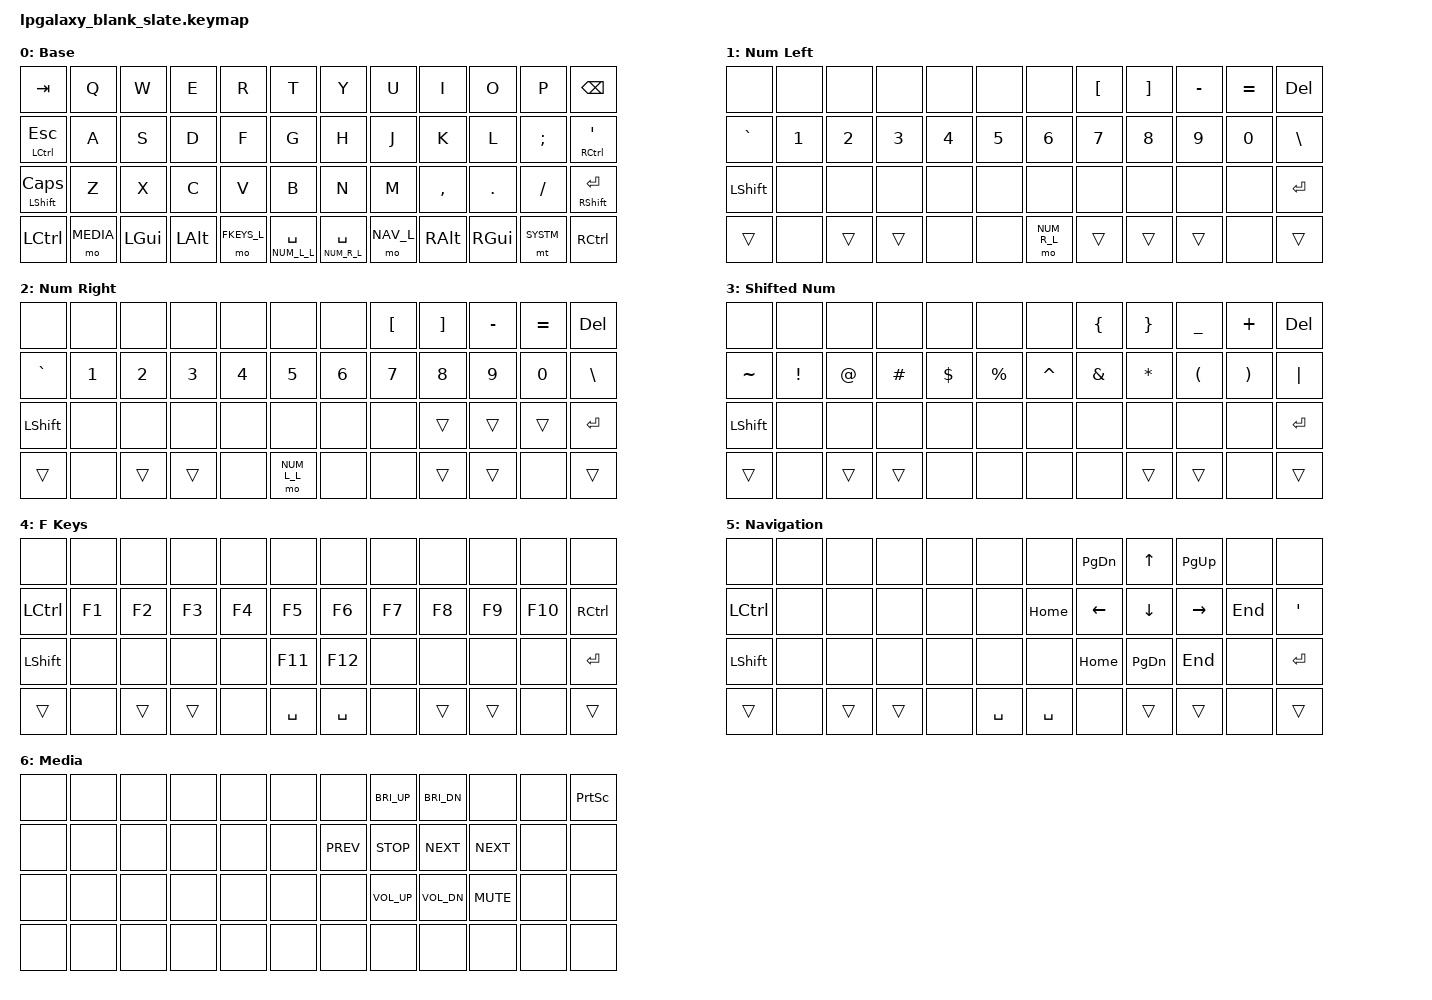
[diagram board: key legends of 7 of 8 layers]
/*
 * Copyright (c) 2022 Pete Johanson
 *
 * SPDX-License-Identifier: MIT
 */

#include <behaviors.dtsi>
#include <dt-bindings/zmk/keys.h>
#include <dt-bindings/zmk/bt.h>
#include <dt-bindings/zmk/outputs.h>

#define NUM_L_L 1
#define NUM_R_L 2
#define NUM_SFT 3
#define FKEYS_L 4
#define NAV_L   5
#define MEDIA   7
#define SYSTM   9


// using layer taps on thumbs, having quick tap as well helps w/ repeating space/backspace
&lt {
    quick_tap_ms = <200>;
};

#define BT(n) BT_SEL n

// tri layer documentation
// https://zmk.dev/docs/features/conditional-layers

/ {
      conditional_layers {
          compatible = "zmk,conditional-layers";
          tri_layer {
              if-layers = <NUM_L_L NUM_R_L>;
              then-layer = <NUM_SFT>;
          };
      };
};

/ {
      keymap {
          compatible = "zmk,keymap";

          base_layer {
              label = "Base";
              bindings = <
&kp   TAB          &kp Q      &kp W     &kp E     &kp R        &kp T              &kp Y              &kp U      &kp I      &kp O     &kp P      &kp BKSP
&mt   LCTRL ESC    &kp A      &kp S     &kp D     &kp F        &kp G              &kp H              &kp J      &kp K      &kp L     &kp SEMI   &mt RCTRL SINGLE_QUOTE
&mt   LSHIFT CAPS  &kp Z      &kp X     &kp C     &kp V        &kp B              &kp N              &kp M      &kp COMMA  &kp DOT   &kp FSLH   &mt RSHIFT RET
&kp   LCTRL        &mo MEDIA  &kp LGUI  &kp LALT  &mo FKEYS_L  &lt NUM_L_L SPACE  &lt NUM_R_L SPACE  &mo NAV_L  &kp RALT   &kp RGUI  &mt SYSTM  &kp RCTRL
              >;
          };

          num_layer_left {
              label = "Num Left";
              bindings = <
&none        &none   &none   &none   &none   &none   &none        &kp LBKT  &kp RBKT  &kp MINUS  &kp EQUAL  &kp DEL
&kp   GRAVE  &kp N1  &kp N2  &kp N3  &kp N4  &kp N5  &kp N6       &kp N7    &kp N8    &kp N9     &kp N0     &kp BSLH
&kp   LSHFT  &none   &none   &none   &none   &none   &none        &none     &none     &none      &none      &kp RET
&trans       &none   &trans  &trans  &none   &none   &mo NUM_R_L  &trans    &trans    &trans     &none      &trans
              >;
          };

          num_layer_right {
              label = "Num Right";
              bindings = <
&none        &none   &none   &none   &none   &none        &none   &kp LBKT  &kp RBKT  &kp MINUS  &kp EQUAL  &kp DEL
&kp   GRAVE  &kp N1  &kp N2  &kp N3  &kp N4  &kp N5       &kp N6  &kp N7    &kp N8    &kp N9     &kp N0     &kp BSLH
&kp   LSHFT  &none   &none   &none   &none   &none        &none   &none     &trans    &trans     &trans     &kp RET
&trans       &none   &trans  &trans  &none   &mo NUM_L_L  &none   &none     &trans    &trans     &none      &trans
              >;
          };

          num_layer_shifted {
              label = "Shifted Num";
              bindings = <
&none        &none     &none   &none     &none       &none        &none      &kp LBRC  &kp RBRC  &kp UNDER  &kp PLUS  &kp DEL
&kp   TILDE  &kp EXCL  &kp AT  &kp HASH  &kp DOLLAR  &kp PERCENT  &kp CARET  &kp AMPS  &kp STAR  &kp LPAR   &kp RPAR  &kp PIPE
&kp   LSHFT  &none     &none   &none     &none       &none        &none      &none     &none     &none      &none     &kp RET
&trans       &none     &trans  &trans    &none       &none        &none      &none     &trans    &trans     &none     &trans
              >;
          };

          fkeys_layer {
              label = "F Keys";
              bindings = <
&none        &none   &none   &none   &none   &none      &none      &none   &none   &none   &none    &none
&kp   LCTRL  &kp F1  &kp F2  &kp F3  &kp F4  &kp F5     &kp F6     &kp F7  &kp F8  &kp F9  &kp F10  &kp RCTRL
&kp   LSHFT  &none   &none   &none   &none   &kp F11    &kp F12    &none   &none   &none   &none    &kp RET
&trans       &none   &trans  &trans  &none   &kp SPACE  &kp SPACE  &none   &trans  &trans  &none    &trans
              >;
          };

          nav_layer {
              label = "Navigation";
              bindings = <
&none        &none  &none   &none   &none  &none      &none      &kp PG_DN  &kp UP     &kp PG_UP  &none    &none
&kp   LCTRL  &none  &none   &none   &none  &none      &kp HOME   &kp LEFT   &kp DOWN   &kp RIGHT  &kp END  &kp SINGLE_QUOTE
&kp   LSHFT  &none  &none   &none   &none  &none      &none      &kp HOME   &kp PG_DN  &kp END    &none    &kp RET
&trans       &none  &trans  &trans  &none  &kp SPACE  &kp SPACE  &none      &trans     &trans     &none    &trans
              >;
          };

          media_layer {
              label = "Media";
              bindings = <
&none    &none  &none  &none  &none  &none  &none       &kp C_BRI_UP  &kp C_BRI_DN  &none       &none  &kp PRINTSCREEN
&none    &none  &none  &none  &none  &none  &kp C_PREV  &kp C_STOP    &kp C_NEXT    &kp C_NEXT  &none  &none
&none    &none  &none  &none  &none  &none  &none       &kp C_VOL_UP  &kp C_VOL_DN  &kp C_MUTE  &none  &none
&none    &none  &none  &none  &none  &none  &none       &none         &none         &none       &none  &none
              >;
          };

          sym_layer {
              label = "System";
              bindings = <
&bt   BT_CLR  &none      &none      &none      &none      &none      &none  &none  &none  &none  &none  &bootloader
&none         &bt BT(0)  &bt BT(1)  &bt BT(2)  &bt BT(3)  &bt BT(4)  &none  &none  &none  &none  &none  &none
&none         &none      &none      &none      &none      &none      &none  &none  &none  &none  &none  &none
&none         &none      &none      &none      &none      &none      &none  &none  &none  &none  &none  &none
              >;
          };

      };
};

